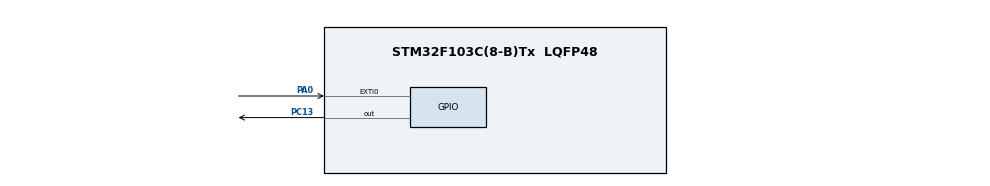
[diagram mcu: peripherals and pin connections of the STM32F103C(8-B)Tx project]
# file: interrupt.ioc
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Mcu.Family=STM32F1
Mcu.Name=STM32F103C(8-B)Tx
Mcu.Package=LQFP48
NVIC.EXTI0_IRQn=true\:0\:0\:false\:false\:true\:true\:true
NVIC.PriorityGroup=NVIC_PRIORITYGROUP_4
PA0-WKUP.Signal=GPXTI0
PA13.Mode=Serial_Wire
PA13.Signal=SYS_JTMS-SWDIO
PA14.Mode=Serial_Wire
PA14.Signal=SYS_JTCK-SWCLK
PC13-TAMPER-RTC.Signal=GPIO_Output
PD0-OSC_IN.Mode=HSE-External-Oscillator
PD0-OSC_IN.Signal=RCC_OSC_IN
PD1-OSC_OUT.Mode=HSE-External-Oscillator
PD1-OSC_OUT.Signal=RCC_OSC_OUT
ProjectManager.HeapSize=0x200
ProjectManager.StackSize=0x400
ProjectManager.TargetToolchain=MDK-ARM V5.27
RCC.APB1Freq_Value=8000000
RCC.APB2Freq_Value=8000000
board=custom

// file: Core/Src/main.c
/* USER CODE BEGIN Header */
/**
  ******************************************************************************
  * @file           : main.c
  * @brief          : Main program body
  ******************************************************************************
  * @attention
  *
  * <h2><center>&copy; Copyright (c) 2021 STMicroelectronics.
  * All rights reserved.</center></h2>
  *
  * This software component is licensed by ST under BSD 3-Clause license,
  * the "License"; You may not use this file except in compliance with the
  * License. You may obtain a copy of the License at:
  *                        opensource.org/licenses/BSD-3-Clause
  *
  ******************************************************************************
  */
/* USER CODE END Header */
 int i = 0;
#include "main.h"

/* USER CODE BEGIN PV */

 char State = 0;
/* USER CODE END PV */

void SystemClock_Config(void);
static void MX_GPIO_Init(void);

int main(void)
{

  /* MCU Configuration--------------------------------------------------------*/

  /* Reset of all peripherals, Initializes the Flash interface and the Systick. */

  LL_APB2_GRP1_EnableClock(LL_APB2_GRP1_PERIPH_AFIO);
  LL_APB1_GRP1_EnableClock(LL_APB1_GRP1_PERIPH_PWR);

  NVIC_SetPriorityGrouping(NVIC_PRIORITYGROUP_4);

  /* System interrupt init*/

  /** NOJTAG: JTAG-DP Disabled and SW-DP Enabled
  */
  LL_GPIO_AF_Remap_SWJ_NOJTAG();

  /* Configure the system clock */
  SystemClock_Config();

  /* Initialize all configured peripherals */
  MX_GPIO_Init();

  /* Infinite loop */
  while (1)
  {

    /* USER CODE BEGIN 3 */

	/* check to see if i has incremented 5 times and turn-on the LED(pin13) if its off and vice versa */
		if (i > 5 && State == 0)
	{
		LL_GPIO_SetOutputPin(GPIOC, LL_GPIO_PIN_13);
		i = 0;
		State = 1;
	}

	if (i > 5 && State == 1)
	{
		LL_GPIO_ResetOutputPin(GPIOC, LL_GPIO_PIN_13);
		i = 0;
		State = 0;
	}
	  }
  /* USER CODE END 3 */
}

void SystemClock_Config(void)
{
  LL_FLASH_SetLatency(LL_FLASH_LATENCY_0);
  while(LL_FLASH_GetLatency()!= LL_FLASH_LATENCY_0)
  {
  }
  LL_RCC_HSI_SetCalibTrimming(16);
  LL_RCC_HSI_Enable();

   /* Wait till HSI is ready */
  while(LL_RCC_HSI_IsReady() != 1)
  {

  }
  LL_RCC_SetAHBPrescaler(LL_RCC_SYSCLK_DIV_1);
  LL_RCC_SetAPB1Prescaler(LL_RCC_APB1_DIV_1);
  LL_RCC_SetAPB2Prescaler(LL_RCC_APB2_DIV_1);
  LL_RCC_SetSysClkSource(LL_RCC_SYS_CLKSOURCE_HSI);

   /* Wait till System clock is ready */
  while(LL_RCC_GetSysClkSource() != LL_RCC_SYS_CLKSOURCE_STATUS_HSI)
  {

  }
  LL_Init1msTick(8000000);
  LL_SetSystemCoreClock(8000000);
}

static void MX_GPIO_Init(void)
{
  LL_EXTI_InitTypeDef EXTI_InitStruct = {0};
  LL_GPIO_InitTypeDef GPIO_InitStruct = {0};

  /* GPIO Ports Clock Enable */
  LL_APB2_GRP1_EnableClock(LL_APB2_GRP1_PERIPH_GPIOC);
  LL_APB2_GRP1_EnableClock(LL_APB2_GRP1_PERIPH_GPIOD);
  LL_APB2_GRP1_EnableClock(LL_APB2_GRP1_PERIPH_GPIOA);

  /**/
  LL_GPIO_ResetOutputPin(GPIOC, LL_GPIO_PIN_13);

  /**/
  GPIO_InitStruct.Pin = LL_GPIO_PIN_13;
  GPIO_InitStruct.Mode = LL_GPIO_MODE_OUTPUT;
  GPIO_InitStruct.Speed = LL_GPIO_SPEED_FREQ_LOW;
  GPIO_InitStruct.OutputType = LL_GPIO_OUTPUT_PUSHPULL;
  LL_GPIO_Init(GPIOC, &GPIO_InitStruct);

  /**/
  LL_GPIO_AF_SetEXTISource(LL_GPIO_AF_EXTI_PORTA, LL_GPIO_AF_EXTI_LINE0);

  /**/
  EXTI_InitStruct.Line_0_31 = LL_EXTI_LINE_0;
  EXTI_InitStruct.LineCommand = ENABLE;
  EXTI_InitStruct.Mode = LL_EXTI_MODE_IT;
  EXTI_InitStruct.Trigger = LL_EXTI_TRIGGER_RISING;
  LL_EXTI_Init(&EXTI_InitStruct);

  /**/
  LL_GPIO_SetPinMode(GPIOA, LL_GPIO_PIN_0, LL_GPIO_MODE_FLOATING);

  /* EXTI interrupt init*/
  NVIC_SetPriority(EXTI0_IRQn, NVIC_EncodePriority(NVIC_GetPriorityGrouping(),0, 0));
  NVIC_EnableIRQ(EXTI0_IRQn);

}

void Error_Handler(void)
{
}

/************************ (C) COPYRIGHT STMicroelectronics *****END OF FILE****/
